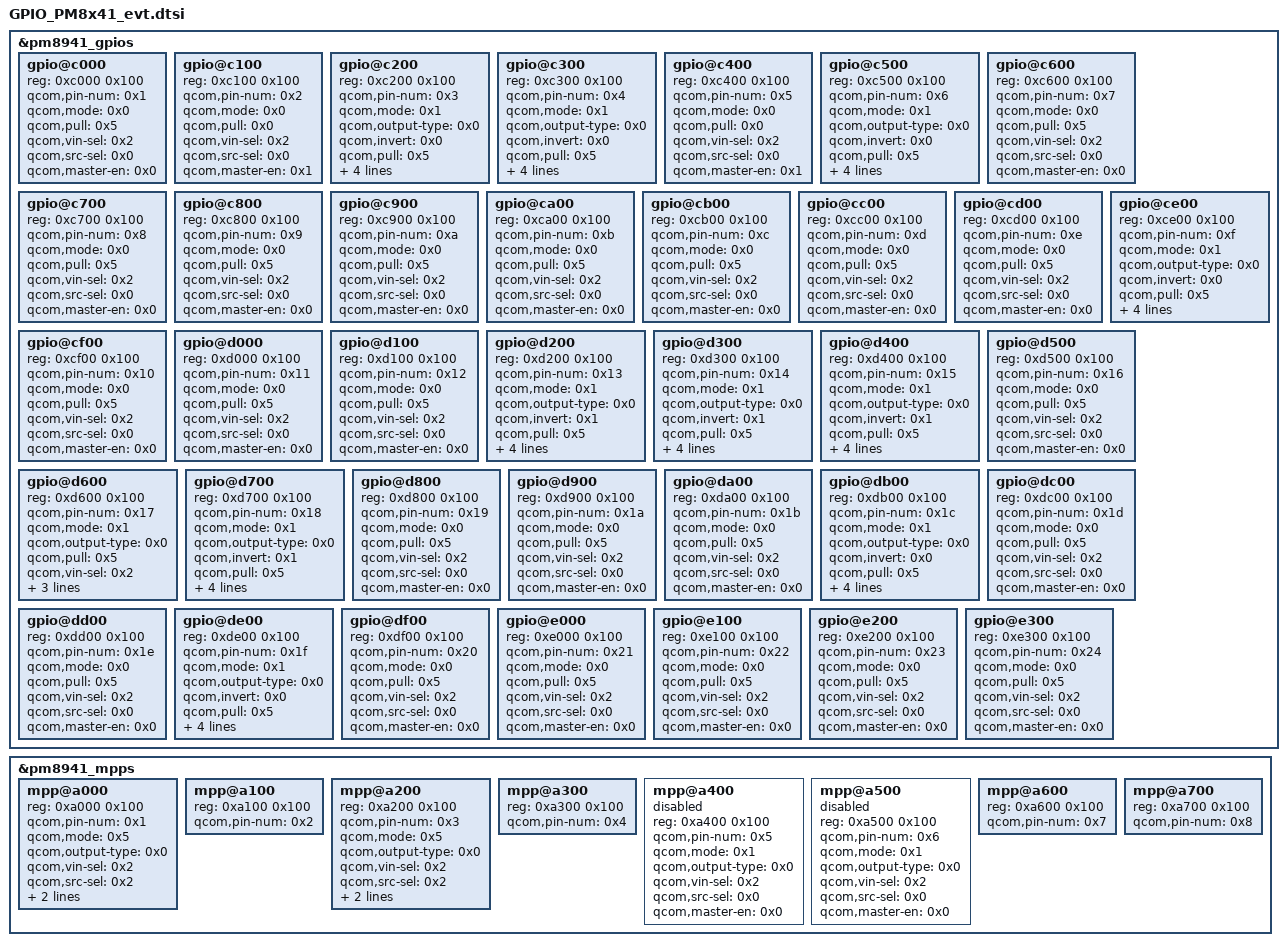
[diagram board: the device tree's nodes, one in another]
/* GPIO */
&pm8941_gpios {
	gpio@c000 { /* PM8941 GPIO 01 */
		reg = <0xc000 0x100>;
		qcom,pin-num = <0x1>;
		qcom,mode = <0x0>;
		qcom,pull = <0x5>;
		qcom,vin-sel = <0x2>;
		qcom,src-sel = <0x0>;
		qcom,master-en = <0x0>;
	};

	gpio@c100 { /* PM8941 GPIO 02 */
		reg = <0xc100 0x100>;
		qcom,pin-num = <0x2>;
		qcom,mode = <0x0>;
		qcom,pull = <0x0>;
		qcom,vin-sel = <0x2>;
		qcom,src-sel = <0x0>;
		qcom,master-en = <0x1>;
	};

	gpio@c200 { /* PM8941 GPIO 03 */
		reg = <0xc200 0x100>;
		qcom,pin-num = <0x3>;
		qcom,mode = <0x1>;
		qcom,output-type = <0x0>;
		qcom,invert = <0x0>;
		qcom,pull = <0x5>;
		qcom,vin-sel = <0x2>;
		qcom,out-strength = <0x2>;
		qcom,src-sel = <0x0>;
		qcom,master-en = <0x1>;
	};

	gpio@c300 { /* PM8941 GPIO 04 */
		reg = <0xc300 0x100>;
		qcom,pin-num = <0x4>;
		qcom,mode = <0x1>;
		qcom,output-type = <0x0>;
		qcom,invert = <0x0>;
		qcom,pull = <0x5>;
		qcom,vin-sel = <0x2>;
		qcom,out-strength = <0x2>;
		qcom,src-sel = <0x0>;
		qcom,master-en = <0x1>;
	};

	gpio@c400 { /* PM8941 GPIO 05 */
		reg = <0xc400 0x100>;
		qcom,pin-num = <0x5>;
		qcom,mode = <0x0>;
		qcom,pull = <0x0>;
		qcom,vin-sel = <0x2>;
		qcom,src-sel = <0x0>;
		qcom,master-en = <0x1>;
	};

	gpio@c500 { /* PM8941 GPIO 06 */
		reg = <0xc500 0x100>;
		qcom,pin-num = <0x6>;
		qcom,mode = <0x1>;
		qcom,output-type = <0x0>;
		qcom,invert = <0x0>;
		qcom,pull = <0x5>;
		qcom,vin-sel = <0x2>;
		qcom,out-strength = <0x2>;
		qcom,src-sel = <0x0>;
		qcom,master-en = <0x1>;
	};

	gpio@c600 { /* PM8941 GPIO 07 */
		reg = <0xc600 0x100>;
		qcom,pin-num = <0x7>;
		qcom,mode = <0x0>;
		qcom,pull = <0x5>;
		qcom,vin-sel = <0x2>;
		qcom,src-sel = <0x0>;
		qcom,master-en = <0x0>;
	};

	gpio@c700 { /* PM8941 GPIO 08 */
		reg = <0xc700 0x100>;
		qcom,pin-num = <0x8>;
		qcom,mode = <0x0>;
		qcom,pull = <0x5>;
		qcom,vin-sel = <0x2>;
		qcom,src-sel = <0x0>;
		qcom,master-en = <0x0>;
	};

	gpio@c800 { /* PM8941 GPIO 09 */
		reg = <0xc800 0x100>;
		qcom,pin-num = <0x9>;
		qcom,mode = <0x0>;
		qcom,pull = <0x5>;
		qcom,vin-sel = <0x2>;
		qcom,src-sel = <0x0>;
		qcom,master-en = <0x0>;
	};

	gpio@c900 { /* PM8941 GPIO 10 */
		reg = <0xc900 0x100>;
		qcom,pin-num = <0xa>;
		qcom,mode = <0x0>;
		qcom,pull = <0x5>;
		qcom,vin-sel = <0x2>;
		qcom,src-sel = <0x0>;
		qcom,master-en = <0x0>;
	};

	gpio@ca00 { /* PM8941 GPIO 11 */
		reg = <0xca00 0x100>;
		qcom,pin-num = <0xb>;
		qcom,mode = <0x0>;
		qcom,pull = <0x5>;
		qcom,vin-sel = <0x2>;
		qcom,src-sel = <0x0>;
		qcom,master-en = <0x0>;
	};

	gpio@cb00 { /* PM8941 GPIO 12 */
		reg = <0xcb00 0x100>;
		qcom,pin-num = <0xc>;
		qcom,mode = <0x0>;
		qcom,pull = <0x5>;
		qcom,vin-sel = <0x2>;
		qcom,src-sel = <0x0>;
		qcom,master-en = <0x0>;
	};

	gpio@cc00 { /* PM8941 GPIO 13 */
		reg = <0xcc00 0x100>;
		qcom,pin-num = <0xd>;
		qcom,mode = <0x0>;
		qcom,pull = <0x5>;
		qcom,vin-sel = <0x2>;
		qcom,src-sel = <0x0>;
		qcom,master-en = <0x0>;
	};

	gpio@cd00 { /* PM8941 GPIO 14 */
		reg = <0xcd00 0x100>;
		qcom,pin-num = <0xe>;
		qcom,mode = <0x0>;
		qcom,pull = <0x5>;
		qcom,vin-sel = <0x2>;
		qcom,src-sel = <0x0>;
		qcom,master-en = <0x0>;
	};

	gpio@ce00 { /* PM8941 GPIO 15 */
		reg = <0xce00 0x100>;
		qcom,pin-num = <0xf>;
		qcom,mode = <0x1>;
		qcom,output-type = <0x0>;
		qcom,invert = <0x0>;
		qcom,pull = <0x5>;
		qcom,vin-sel = <0x2>;
		qcom,out-strength = <0x1>;
		qcom,src-sel = <0x2>;
		qcom,master-en = <0x1>;
	};

	gpio@cf00 { /* PM8941 GPIO 16 */
		reg = <0xcf00 0x100>;
		qcom,pin-num = <0x10>;
		qcom,mode = <0x0>;
		qcom,pull = <0x5>;
		qcom,vin-sel = <0x2>;
		qcom,src-sel = <0x0>;
		qcom,master-en = <0x0>;
	};

	gpio@d000 { /* PM8941 GPIO 17 */
		reg = <0xd000 0x100>;
		qcom,pin-num = <0x11>;
		qcom,mode = <0x0>;
		qcom,pull = <0x5>;
		qcom,vin-sel = <0x2>;
		qcom,src-sel = <0x0>;
		qcom,master-en = <0x0>;
	};

	gpio@d100 { /* PM8941 GPIO 18 */
		reg = <0xd100 0x100>;
		qcom,pin-num = <0x12>;
		qcom,mode = <0x0>;
		qcom,pull = <0x5>;
		qcom,vin-sel = <0x2>;
		qcom,src-sel = <0x0>;
		qcom,master-en = <0x0>;
	};

	gpio@d200 { /* PM8941 GPIO 19 */
		reg = <0xd200 0x100>;
		qcom,pin-num = <0x13>;
		qcom,mode = <0x1>;
		qcom,output-type = <0x0>;
		qcom,invert = <0x1>; /* Set high due to initial in bootloader */
		qcom,pull = <0x5>;
		qcom,vin-sel = <0x2>;
		qcom,out-strength = <0x2>;
		qcom,src-sel = <0x0>;
		qcom,master-en = <0x1>;
	};

	gpio@d300 { /* PM8941 GPIO 20 */
		reg = <0xd300 0x100>;
		qcom,pin-num = <0x14>;
		qcom,mode = <0x1>;
		qcom,output-type = <0x0>;
		qcom,invert = <0x1>; /* Set high due to initial in bootloader */
		qcom,pull = <0x5>;
		qcom,vin-sel = <0x2>;
		qcom,out-strength = <0x2>;
		qcom,src-sel = <0x0>;
		qcom,master-en = <0x1>;
	};

	gpio@d400 { /* PM8941 GPIO 21 */
		reg = <0xd400 0x100>;
		qcom,pin-num = <0x15>;
		qcom,mode = <0x1>;
		qcom,output-type = <0x0>;
		qcom,invert = <0x1>;
		qcom,pull = <0x5>;
		qcom,vin-sel = <0x2>;
		qcom,out-strength = <0x2>;
		qcom,src-sel = <0x2>;
		qcom,master-en = <0x1>;
	};

	gpio@d500 { /* PM8941 GPIO 22 */
		reg = <0xd500 0x100>;
		qcom,pin-num = <0x16>;
		qcom,mode = <0x0>;
		qcom,pull = <0x5>;
		qcom,vin-sel = <0x2>;
		qcom,src-sel = <0x0>;
		qcom,master-en = <0x0>;
	};

	gpio@d600 { /* PM8941 GPIO 23 */
		reg = <0xd600 0x100>;
		qcom,pin-num = <0x17>;
		qcom,mode = <0x1>;
		qcom,output-type = <0x0>;
		qcom,pull = <0x5>;
		qcom,vin-sel = <0x2>;
		qcom,out-strength = <0x3>;
		qcom,src-sel = <0x3>;
		qcom,master-en = <0x1>;
	};

	gpio@d700 { /* PM8941 GPIO 24 */
		reg = <0xd700 0x100>;
		qcom,pin-num = <0x18>;
		qcom,mode = <0x1>;
		qcom,output-type = <0x0>;
		qcom,invert = <0x1>; /* Set high due to initial in bootloader */
		qcom,pull = <0x5>;
		qcom,vin-sel = <0x2>;
		qcom,out-strength = <0x2>;
		qcom,src-sel = <0x0>;
		qcom,master-en = <0x1>;
	};

	gpio@d800 { /* PM8941 GPIO 25 */
		reg = <0xd800 0x100>;
		qcom,pin-num = <0x19>;
		qcom,mode = <0x0>;
		qcom,pull = <0x5>;
		qcom,vin-sel = <0x2>;
		qcom,src-sel = <0x0>;
		qcom,master-en = <0x0>;
	};

	gpio@d900 { /* PM8941 GPIO 26 */
		reg = <0xd900 0x100>;
		qcom,pin-num = <0x1a>;
		qcom,mode = <0x0>;
		qcom,pull = <0x5>;
		qcom,vin-sel = <0x2>;
		qcom,src-sel = <0x0>;
		qcom,master-en = <0x0>;
	};

	gpio@da00 { /* PM8941 GPIO 27 */
		reg = <0xda00 0x100>;
		qcom,pin-num = <0x1b>;
		qcom,mode = <0x0>;
		qcom,pull = <0x5>;
		qcom,vin-sel = <0x2>;
		qcom,src-sel = <0x0>;
		qcom,master-en = <0x0>;
	};

	gpio@db00 { /* PM8941 GPIO 28 */
		reg = <0xdb00 0x100>;
		qcom,pin-num = <0x1c>;
		qcom,mode = <0x1>;
		qcom,output-type = <0x0>;
		qcom,invert = <0x0>;
		qcom,pull = <0x5>;
		qcom,vin-sel = <0x2>;
		qcom,out-strength = <0x2>;
		qcom,src-sel = <0x0>;
		qcom,master-en = <0x1>;
	};

	gpio@dc00 { /* PM8941 GPIO 29 */
		reg = <0xdc00 0x100>;
		qcom,pin-num = <0x1d>;
		qcom,mode = <0x0>;
		qcom,pull = <0x5>;
		qcom,vin-sel = <0x2>;
		qcom,src-sel = <0x0>;
		qcom,master-en = <0x0>;
	};

	gpio@dd00 { /* PM8941 GPIO 30 */
		reg = <0xdd00 0x100>;
		qcom,pin-num = <0x1e>;
		qcom,mode = <0x0>;
		qcom,pull = <0x5>;
		qcom,vin-sel = <0x2>;
		qcom,src-sel = <0x0>;
		qcom,master-en = <0x0>;
	};

	gpio@de00 { /* PM8941 GPIO 31 */
		reg = <0xde00 0x100>;
		qcom,pin-num = <0x1f>;
		qcom,mode = <0x1>;
		qcom,output-type = <0x0>;
		qcom,invert = <0x0>;
		qcom,pull = <0x5>;
		qcom,vin-sel = <0x2>;
		qcom,out-strength = <0x2>;
		qcom,src-sel = <0x2>;
		qcom,master-en = <0x1>;
	};

	gpio@df00 { /*  PM8941 GPIO 32 */
		reg = <0xdf00 0x100>;
		qcom,pin-num = <0x20>;
		qcom,mode = <0x0>;
		qcom,pull = <0x5>;
		qcom,vin-sel = <0x2>;
		qcom,src-sel = <0x0>;
		qcom,master-en = <0x0>;
	};

	gpio@e000 { /* PM8941 GPIO 33 */
		reg = <0xe000 0x100>;
		qcom,pin-num = <0x21>;
		qcom,mode = <0x0>;
		qcom,pull = <0x5>;
		qcom,vin-sel = <0x2>;
		qcom,src-sel = <0x0>;
		qcom,master-en = <0x0>;
	};

	gpio@e100 { /* PM8941 GPIO 34 */
		reg = <0xe100 0x100>;
		qcom,pin-num = <0x22>;
		qcom,mode = <0x0>;
		qcom,pull = <0x5>;
		qcom,vin-sel = <0x2>;
		qcom,src-sel = <0x0>;
		qcom,master-en = <0x0>;
	};

	gpio@e200 { /* PM8941 GPIO 35 */
		reg = <0xe200 0x100>;
		qcom,pin-num = <0x23>;
		qcom,mode = <0x0>;
		qcom,pull = <0x5>;
		qcom,vin-sel = <0x2>;
		qcom,src-sel = <0x0>;
		qcom,master-en = <0x0>;
	};

	gpio@e300 { /* PM8941 GPIO 36 */
		reg = <0xe300 0x100>;
		qcom,pin-num = <0x24>;
		qcom,mode = <0x0>;
		qcom,pull = <0x5>;
		qcom,vin-sel = <0x2>;
		qcom,src-sel = <0x0>;
		qcom,master-en = <0x0>;
	};
};

/* MPP */
&pm8941_mpps {
	mpp@a000 { /* PM8941 MPP 01 */
		reg = <0xa000 0x100>;
		qcom,pin-num = <0x1>;
		status = "ok";
		qcom,mode = <0x5>;
		qcom,output-type = <0x0>;
		qcom,vin-sel = <0x2>;
		qcom,src-sel = <0x2>;
		qcom,aout-ref = <0x3>;
		qcom,master-en = <0x1>;
	};

	mpp@a100 { /* PM8941 MPP 02 */
		reg = <0xa100 0x100>;
		qcom,pin-num = <0x2>;
	};

	mpp@a200 { /* PM8941 MPP 03 */
		reg = <0xa200 0x100>;
		qcom,pin-num = <0x3>;
		qcom,mode = <0x5>;
		qcom,output-type = <0x0>;
		qcom,vin-sel = <0x2>;
		qcom,src-sel = <0x2>;
		qcom,aout-ref = <0x3>;
		qcom,master-en = <0x1>;
	};

	mpp@a300 { /* PM8941 MPP 04 */
		reg = <0xa300 0x100>;
		qcom,pin-num = <0x4>;
	};

	mpp@a400 { /* PM8941 MPP 05 */
		reg = <0xa400 0x100>;
		qcom,pin-num = <0x5>;
		qcom,mode = <0x1>;
		qcom,output-type = <0x0>;
		qcom,vin-sel = <0x2>;
		qcom,src-sel = <0x0>;
		qcom,master-en = <0x0>;
		status = "disabled";
	};

	mpp@a500 { /* PM8941 MPP 06 */
		reg = <0xa500 0x100>;
		qcom,pin-num = <0x6>;
		qcom,mode = <0x1>;
		qcom,output-type = <0x0>;
		qcom,vin-sel = <0x2>;
		qcom,src-sel = <0x0>;
		qcom,master-en = <0x0>;
		status = "disabled";
	};

	mpp@a600 { /* PM8941 MPP 07 */
		reg = <0xa600 0x100>;
		qcom,pin-num = <0x7>;
	};

	mpp@a700 { /* PM8941 MPP 08 */
		reg = <0xa700 0x100>;
		qcom,pin-num = <0x8>;
	};
};

